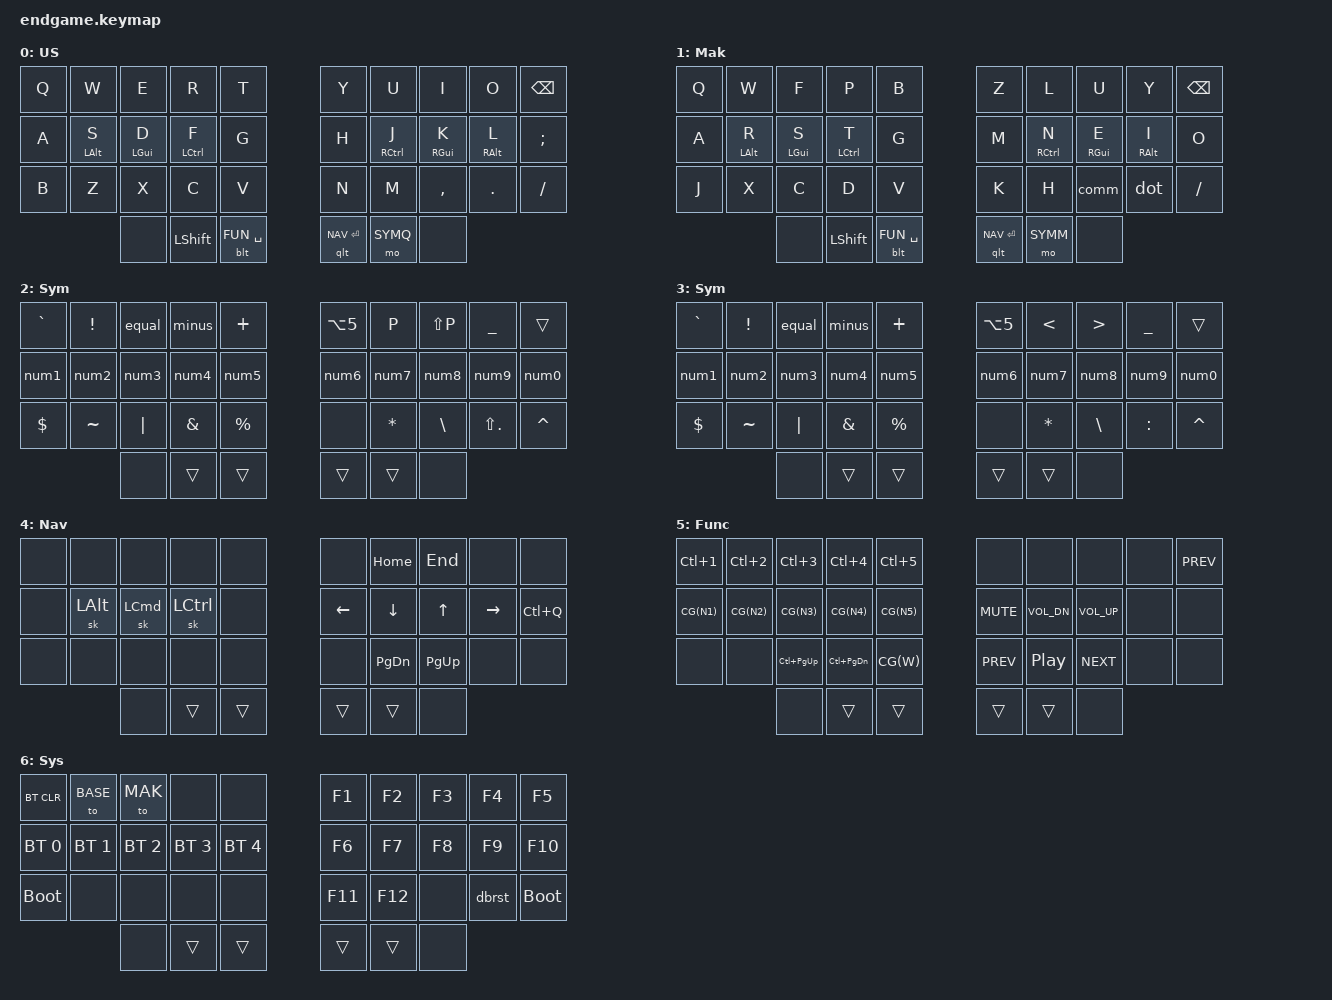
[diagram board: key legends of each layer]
#include <behaviors.dtsi>
#include <dt-bindings/zmk/keys.h>
#include <dt-bindings/zmk/rgb.h>
#include <dt-bindings/zmk/bt.h>
#include <dt-bindings/zmk/outputs.h>

    
/ {
    #define ENDGAME
    #include "smol.dtsi"

    keymap {
        compatible = "zmk,keymap";

        default_layer {
            display-name = "US";
            bindings = <
                &kp Q      &kp W       &kp E       &kp R          &kp T          &kp Y          &kp U          &kp I       &kp O       &kp BSPC
                &kp A      &hml LALT S &hml LGUI D &hml LCTRL F   &kp G          &kp H          &hmr RCTRL J   &hmr RGUI K &hmr RALT L &kp SEMI
                &kp B      &kp Z       &kp X       &kp C          &kp V          &kp N          &kp M          &kp COMMA   &kp DOT     &kp FSLH
                &none                              &kp LSHFT      &blt FUN SPACE &qlt NAV RET   &mo SYMQ                               &none
            >;
        };
        mak_layer {
            display-name = "Mak";
            bindings = <
                &kp Q      &kp W       &kp F       &kp P          &kp B          &kp Z          &kp L          &kp U       &kp Y       &kp BSPC
                &kp A      &hml LALT R &hml LGUI S &hml LCTRL T   &kp G          &kp M          &hmr RCTRL N   &hmr RGUI E &hmr RALT I &kp O
                &kp J      &kp X       &kp C       &kp D          &kp V          &kp K          &kp H          &comm       &dot        &kp FSLH
                &none                              &kp LSHFT      &blt FUN SPACE &qlt NAV RET   &mo SYMM                               &none
            >;
        };
        sym_qwerty {
            display-name = "Sym";   
            bindings = <
                &kp GRAVE  &kp EXCL   &equal      &minus          &kp PLUS      &kp LA(N5)      &kp P          &kp LS(P)   &kp UNDER  &trans   
                &num1      &num2      &num3       &num4           &num5         &num6           &num7          &num8       &num9      &num0    
                &kp DLLR   &kp TILDE  &kp PIPE    &kp AMPS        &kp PRCNT     &none           &kp STAR       &kp BSLH    &kp LS(DOT)&kp CARET 
                &none                             &trans          &trans        &trans          &trans                                &none
            >;
        };
        sym_mak {
            display-name = "Sym";   
            bindings = <
                &kp GRAVE  &kp EXCL   &equal      &minus          &kp PLUS      &kp LA(N5)      &kp LT         &kp GT      &kp UNDER  &trans   
                &num1      &num2      &num3       &num4           &num5         &num6           &num7          &num8       &num9      &num0    
                &kp DLLR   &kp TILDE  &kp PIPE    &kp AMPS        &kp PRCNT     &none           &kp STAR       &kp BSLH    &kp COLON  &kp CARET 
                &none                             &trans          &trans        &trans          &trans                                &none
            >;
        };
        nav_layer {
            display-name = "Nav";
            bindings = <
                &none       &none       &none      &none          &none         &none           &kp HOME       &kp END      &none      &none   
                &none       &sk LALT    &sk LCMD   &sk LCTRL      &none         &kp LEFT        &kp DOWN       &kp UP       &kp RIGHT  &kp LC(Q)
                &none       &none       &none      &none          &none         &none           &kp PG_DN      &kp PG_UP    &none      &none 
                &none                             &trans          &trans        &trans          &trans                                &none
            >;
        };
        function_layer {
            display-name = "Func";
            bindings = <
                &kp LC(N1)    &kp LC(N2)   &kp LC(N3)   &kp LC(N4)    &kp LC(N5)    &none      &none         &none        &none        &kp C_PREV
                &kp CG(N1)    &kp CG(N2)   &kp CG(N3)   &kp CG(N4)    &kp CG(N5)    &kp C_MUTE &kp C_VOL_DN  &kp C_VOL_UP &none        &none      
                &none         &none        &kp LC(PG_UP)&kp LC(PG_DN) &kp CG(W)     &kp C_PREV &kp C_PP      &kp C_NEXT   &none        &none 
                &none                             &trans          &trans        &trans          &trans                                &none
            >;
        };
        system_layer {
            display-name = "Sys";
            bindings = <
                &bt BT_CLR   &to BASE       &to MAK      &none          &none        &kp F1    &kp F2        &kp F3       &kp F4       &kp F5
                &bt BT_SEL 0 &bt BT_SEL 1   &bt BT_SEL 2 &bt BT_SEL 3   &bt BT_SEL 4 &kp F6    &kp F7        &kp F8       &kp F9       &kp F10      
                &bootloader  &none          &none        &none          &none        &kp F11   &kp F12       &none        &dbrst       &bootloader
                &none                             &trans          &trans        &trans          &trans                                &none
            >;
        };
    };
};
